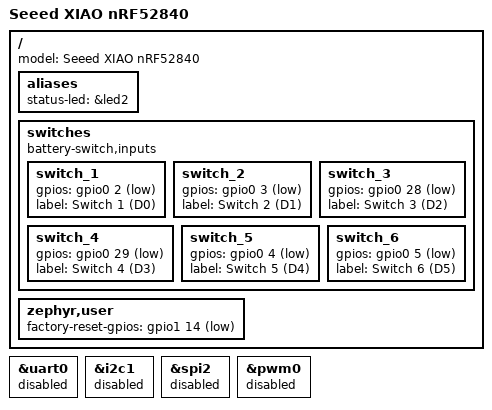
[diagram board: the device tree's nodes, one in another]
/*
 * SPDX-License-Identifier: Apache-2.0
 *
 * Seeed Studio XIAO nRF52840 (xiao_ble/nrf52840).
 *
 * Switch wiring: every switch goes between its pin and GND. The internal
 * pull-up is used, no external parts are needed.
 *
 *   Switch 1 -> D0 (P0.02)      Switch 4 -> D3 (P0.29)
 *   Switch 2 -> D1 (P0.03)      Switch 5 -> D4 (P0.04)
 *   Switch 3 -> D2 (P0.28)      Switch 6 -> D5 (P0.05)
 *
 * Set `switch-type` per switch (default "momentary"); it can also be changed
 * later from the smart home app:
 *   "momentary"  push button
 *   "latching"   rocker/toggle; every change of position is reported as a
 *                short press
 * Delete the nodes of switches that are not connected; their Matter
 * endpoints are then disabled.
 *
 * Factory reset: hold D9 (P1.14) to GND for 5 s (see zephyr,user below).
 *
 * Battery: connect + to 3V3 and - to GND (2x AAA or CR2032). The battery
 * voltage is measured internally on the nRF52840 VDD rail.
 */

/ {
	/* Shown as the hardware version by Matter controllers. */
	model = "Seeed XIAO nRF52840";

	aliases {
		status-led = &led2; /* blue */
	};

	switches {
		compatible = "battery-switch,inputs";

		switch_1 {
			gpios = <&gpio0 2 (GPIO_PULL_UP | GPIO_ACTIVE_LOW)>;
			label = "Switch 1 (D0)";
		};

		switch_2 {
			gpios = <&gpio0 3 (GPIO_PULL_UP | GPIO_ACTIVE_LOW)>;
			label = "Switch 2 (D1)";
		};

		switch_3 {
			gpios = <&gpio0 28 (GPIO_PULL_UP | GPIO_ACTIVE_LOW)>;
			label = "Switch 3 (D2)";
		};

		switch_4 {
			gpios = <&gpio0 29 (GPIO_PULL_UP | GPIO_ACTIVE_LOW)>;
			label = "Switch 4 (D3)";
		};

		switch_5 {
			gpios = <&gpio0 4 (GPIO_PULL_UP | GPIO_ACTIVE_LOW)>;
			label = "Switch 5 (D4)";
		};

		switch_6 {
			gpios = <&gpio0 5 (GPIO_PULL_UP | GPIO_ACTIVE_LOW)>;
			label = "Switch 6 (D5)";
		};
	};

	zephyr,user {
		/*
		 * Factory reset pad: D9 (P1.14), on the edge with the power
		 * pins, two pads away from 3V3. Hold it to GND for 5 s to erase
		 * the Matter fabrics and Thread network. It is not a switch input,
		 * so no switch gesture can trigger a reset. Leave it unconnected,
		 * or wire it to a service button inside the enclosure.
		 */
		factory-reset-gpios = <&gpio1 14 (GPIO_PULL_UP | GPIO_ACTIVE_LOW)>;
	};
};

/* XIAO nRF52840 ships with SoftDevice S140 v7: the application starts at 0x27000. */
#define UF2_APP_START 0x27000
#include "uf2_matter_layout.dtsi"

/* Peripherals that are not used; disabling them avoids idle current. */
&uart0 {
	status = "disabled";
};

&i2c1 {
	status = "disabled";
};

&spi2 {
	status = "disabled";
};

&pwm0 {
	status = "disabled";
};

#include "battery_switch_common.dtsi"
